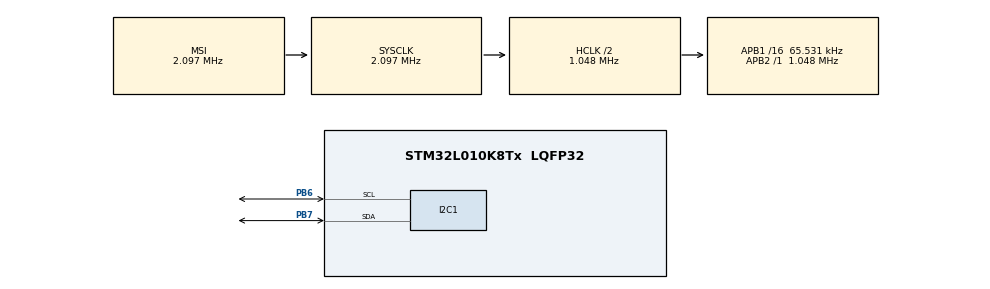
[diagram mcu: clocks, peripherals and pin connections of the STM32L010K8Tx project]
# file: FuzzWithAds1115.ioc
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I2C1.Timing=0x00000000
Mcu.Family=STM32L0
Mcu.Name=STM32L010K8Tx
Mcu.Package=LQFP32
PA13.Mode=Serial_Wire
PA13.Signal=SYS_SWDIO
PA14.Mode=Serial_Wire
PA14.Signal=SYS_SWCLK
PB6.Mode=I2C
PB6.Signal=I2C1_SCL
PB7.Mode=I2C
PB7.Signal=I2C1_SDA
ProjectManager.HeapSize=0x200
ProjectManager.StackSize=0x400
ProjectManager.TargetToolchain=STM32CubeIDE
RCC.AHBCLKDivider=RCC_SYSCLK_DIV2
RCC.AHBFreq_Value=1048500
RCC.APB1CLKDivider=RCC_HCLK_DIV16
RCC.APB1Freq_Value=65531.25
RCC.APB1TimFreq_Value=131062.5
RCC.APB2Freq_Value=1048500
RCC.APB2TimFreq_Value=1048500
RCC.HCLKFreq_Value=1048500
RCC.HSI16_VALUE=16000000
RCC.HSI_VALUE=16000000
RCC.LSE_VALUE=32768
RCC.MSI_VALUE=2097000
RCC.SYSCLKFreq_VALUE=2097000
RCC.VCOOutputFreq_Value=48000000
board=custom

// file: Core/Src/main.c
/* USER CODE BEGIN Header */
/**
  ******************************************************************************
  * @file           : main.c
  * @brief          : Main program body
  ******************************************************************************
  * @attention
  *
  * Copyright (c) 2022 STMicroelectronics.
  * All rights reserved.
  *
  * This software is licensed under terms that can be found in the LICENSE file
  * in the root directory of this software component.
  * If no LICENSE file comes with this software, it is provided AS-IS.
  *
  ******************************************************************************
  */
/* USER CODE END Header */
#include "main.h"

/* USER CODE BEGIN Includes */
#include <string.h>
#include <stdlib.h>
#include <math.h>
/* USER CODE END Includes */

/* USER CODE BEGIN PD */
#define GROOVELCD_ADDR 0x3e<<1
#define ADS1115_ADDRESS 0x48<<1
/* USER CODE END PD */

I2C_HandleTypeDef hi2c1;

/* USER CODE BEGIN PV */
I2C_HandleTypeDef hi2c1;
/* USER CODE END PV */

void SystemClock_Config(void);
static void MX_GPIO_Init(void);
static void MX_I2C1_Init(void);

/* USER CODE BEGIN 0 */
unsigned char ADSwrite[6];
int16_t reading;
float voltage[3];
const float voltageConv = 6.144 / 32768.0;
/* USER CODE END 0 */

int main(void)
{

  /* MCU Configuration--------------------------------------------------------*/

  /* Reset of all peripherals, Initializes the Flash interface and the Systick. */
  HAL_Init();

  /* Configure the system clock */
  SystemClock_Config();

  /* Initialize all configured peripherals */
  MX_GPIO_Init();
  MX_I2C1_Init();
  /* USER CODE BEGIN 2 */
  uint8_t data_t [2];
  data_t[0] = 0x80;
  data_t[1] = 0x28;
  HAL_I2C_Master_Transmit(&hi2c1, (uint16_t)GROOVELCD_ADDR, (uint8_t*)data_t, 2, 50);
  HAL_Delay(1);

  data_t[0] = 0x80;
  data_t[1] = 0x0C;
  HAL_I2C_Master_Transmit(&hi2c1, (uint16_t)GROOVELCD_ADDR, (uint8_t*)data_t, 2, 50);

  data_t[0] = 0x80;
  data_t[1] = 0x01;
  HAL_I2C_Master_Transmit(&hi2c1, (uint16_t)GROOVELCD_ADDR, (uint8_t*)data_t, 2, 50);

  data_t[0] = 0x80;
  data_t[1] = 0x06;
  HAL_I2C_Master_Transmit(&hi2c1, (uint16_t)GROOVELCD_ADDR, (uint8_t*)data_t, 2, 50);
  HAL_Delay(1);

  char *str = malloc (6);
  /* USER CODE END 2 */

  /* Infinite loop */
  /* USER CODE BEGIN WHILE */
  while (1)
  {
	  data_t[0] = 0x80;
	  data_t[1] = 0x03;
	  HAL_I2C_Master_Transmit(&hi2c1, (uint16_t)GROOVELCD_ADDR, (uint8_t*)data_t, 2, 50);
	  HAL_Delay(1);

	  Print(GROOVELCD_ADDR, "Q1:-");
    /* USER CODE END WHILE */

    /* USER CODE BEGIN 3 */
	  for(int i = 0; i<3; i++){
		  ADSwrite[0] = 0x01;
		  switch(i) {
				  case(0):
				  	  ADSwrite[1] = 0xC1;
				  break;
				  case(1):
				  	  ADSwrite[1] = 0xD1;
				  break;
				  case(2):
					  ADSwrite[1] = 0xE1;
				  break;
		  }
		  ADSwrite[2] = 0x83;
		  HAL_I2C_Master_Transmit(&hi2c1, ADS1115_ADDRESS, ADSwrite, 3, 100);
		  ADSwrite[0] = 0x00;
		  HAL_I2C_Master_Transmit(&hi2c1, ADS1115_ADDRESS, ADSwrite, 1, 100);
		  HAL_Delay(20);
		  HAL_I2C_Master_Receive(&hi2c1, ADS1115_ADDRESS, ADSwrite, 2, 100);
		  reading = (ADSwrite[0] << 8 | ADSwrite[1]);
		  if(reading < 0){
			  reading = 0;
		  }
		  voltage[i] = reading * voltageConv;
	  }

	  sprintf (str, "%.2f", voltage[0]);
	  Print(GROOVELCD_ADDR, str);

	  /*Shift to second line*/
	  data_t[0] = 0x80;
	  data_t[1] = 0xC0;
	  HAL_I2C_Master_Transmit(&hi2c1, (uint16_t)GROOVELCD_ADDR, (uint8_t*)data_t, 2, 50);
	  /**/
	  Print(GROOVELCD_ADDR, "Q2:-");
	  sprintf (str, "%.2f", voltage[1]);
	  Print(GROOVELCD_ADDR, str);

	  Print(GROOVELCD_ADDR, " V:-");
	  sprintf (str, "%.2f", voltage[2]);
	  Print(GROOVELCD_ADDR, str);
	  HAL_Delay(20);
  }
  /* USER CODE END 3 */
}

void SystemClock_Config(void)
{
  RCC_OscInitTypeDef RCC_OscInitStruct = {0};
  RCC_ClkInitTypeDef RCC_ClkInitStruct = {0};
  RCC_PeriphCLKInitTypeDef PeriphClkInit = {0};

  /** Configure the main internal regulator output voltage
  */
  __HAL_PWR_VOLTAGESCALING_CONFIG(PWR_REGULATOR_VOLTAGE_SCALE1);

  /** Initializes the RCC Oscillators according to the specified parameters
  * in the RCC_OscInitTypeDef structure.
  */
  RCC_OscInitStruct.OscillatorType = RCC_OSCILLATORTYPE_MSI;
  RCC_OscInitStruct.MSIState = RCC_MSI_ON;
  RCC_OscInitStruct.MSICalibrationValue = 0;
  RCC_OscInitStruct.MSIClockRange = RCC_MSIRANGE_5;
  RCC_OscInitStruct.PLL.PLLState = RCC_PLL_NONE;
  if (HAL_RCC_OscConfig(&RCC_OscInitStruct) != HAL_OK)
  {
    Error_Handler();
  }

  /** Initializes the CPU, AHB and APB buses clocks
  */
  RCC_ClkInitStruct.ClockType = RCC_CLOCKTYPE_HCLK|RCC_CLOCKTYPE_SYSCLK
                              |RCC_CLOCKTYPE_PCLK1|RCC_CLOCKTYPE_PCLK2;
  RCC_ClkInitStruct.SYSCLKSource = RCC_SYSCLKSOURCE_MSI;
  RCC_ClkInitStruct.AHBCLKDivider = RCC_SYSCLK_DIV2;
  RCC_ClkInitStruct.APB1CLKDivider = RCC_HCLK_DIV16;
  RCC_ClkInitStruct.APB2CLKDivider = RCC_HCLK_DIV1;

  if (HAL_RCC_ClockConfig(&RCC_ClkInitStruct, FLASH_LATENCY_0) != HAL_OK)
  {
    Error_Handler();
  }
  PeriphClkInit.PeriphClockSelection = RCC_PERIPHCLK_I2C1;
  PeriphClkInit.I2c1ClockSelection = RCC_I2C1CLKSOURCE_PCLK1;
  if (HAL_RCCEx_PeriphCLKConfig(&PeriphClkInit) != HAL_OK)
  {
    Error_Handler();
  }
}

static void MX_I2C1_Init(void)
{

  hi2c1.Instance = I2C1;
  hi2c1.Init.Timing = 0x00000000;
  hi2c1.Init.OwnAddress1 = 0;
  hi2c1.Init.AddressingMode = I2C_ADDRESSINGMODE_7BIT;
  hi2c1.Init.DualAddressMode = I2C_DUALADDRESS_DISABLE;
  hi2c1.Init.OwnAddress2 = 0;
  hi2c1.Init.OwnAddress2Masks = I2C_OA2_NOMASK;
  hi2c1.Init.GeneralCallMode = I2C_GENERALCALL_DISABLE;
  hi2c1.Init.NoStretchMode = I2C_NOSTRETCH_DISABLE;
  if (HAL_I2C_Init(&hi2c1) != HAL_OK)
  {
    Error_Handler();
  }

  /** Configure Analogue filter
  */
  if (HAL_I2CEx_ConfigAnalogFilter(&hi2c1, I2C_ANALOGFILTER_ENABLE) != HAL_OK)
  {
    Error_Handler();
  }

  /** Configure Digital filter
  */
  if (HAL_I2CEx_ConfigDigitalFilter(&hi2c1, 0) != HAL_OK)
  {
    Error_Handler();
  }

}

static void MX_GPIO_Init(void)
{

  /* GPIO Ports Clock Enable */
  __HAL_RCC_GPIOA_CLK_ENABLE();
  __HAL_RCC_GPIOB_CLK_ENABLE();

}

/* USER CODE BEGIN 4 */
void Print(uint16_t addre, uint8_t *str)
{
	uint8_t data_a[strlen(str)];
	data_a[0] = 0x40;
	int i;
	for(i=0; str[i]!=0; i++)
	{
		data_a[1+i] = str[i];
	}
	HAL_I2C_Master_Transmit(&hi2c1, (uint16_t)addre, (uint8_t*)data_a, 1+strlen(str), 50);
}
/* USER CODE END 4 */

void Error_Handler(void)
{
  __disable_irq();
  while (1)
  {
  }
}
